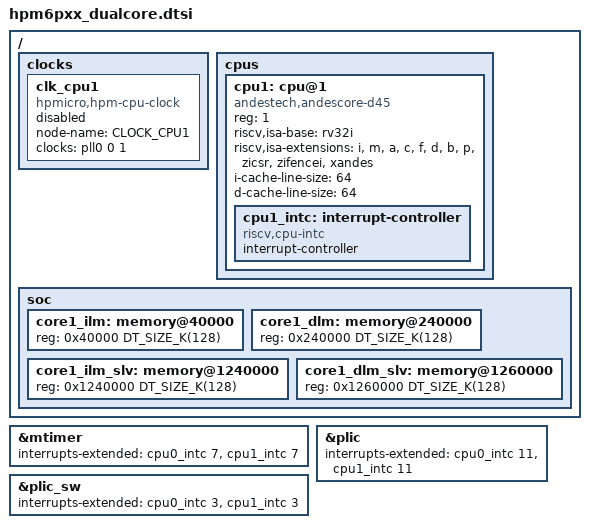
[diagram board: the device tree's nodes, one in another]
/*
* Copyright (c) 2026 HPMicro
* SPDX-License-Identifier: Apache-2.0
*/

#include <mem.h>
#include <freq.h>

/ {
	clocks {
		clk_cpu1: clk_cpu1 {
			#clock-cells = <0>;
			compatible = "hpmicro,hpm-cpu-clock";
			node-name = <CLOCK_CPU1>;
			clocks = <&pll0 0 1>;
			status = "disabled";
		};
	};

	cpus {
		cpu1: cpu@1 {
			compatible = "andestech,andescore-d45", "riscv";
			reg = <1>;
			status = "okay";
			riscv,isa-base = "rv32i";
			riscv,isa-extensions = "i", "m", "a", "c", "f", "d", "b", "p", "zicsr", "zifencei",
				"xandes";
			i-cache-line-size = <64>;
			d-cache-line-size = <64>;
			cpu1_intc: interrupt-controller {
				compatible = "riscv,cpu-intc";
				#address-cells = <0>;
				#interrupt-cells = <1>;
				interrupt-controller;
			};
		};
	};

	soc {
		core1_ilm: memory@40000 {
			reg = <0x40000 DT_SIZE_K(128)>;
		};

		core1_dlm: memory@240000 {
			reg = <0x240000 DT_SIZE_K(128)>;
		};

		core1_ilm_slv: memory@1240000 {
			reg = <0x1240000 DT_SIZE_K(128)>;
		};

		core1_dlm_slv: memory@1260000 {
			reg = <0x1260000 DT_SIZE_K(128)>;
		};
	};
};

&mtimer {
	interrupts-extended = <&cpu0_intc 7 &cpu1_intc 7>;
};

&plic {
	interrupts-extended = <&cpu0_intc 11 &cpu1_intc 11>;
};

&plic_sw {
	interrupts-extended = <&cpu0_intc 3 &cpu1_intc 3>;
};
